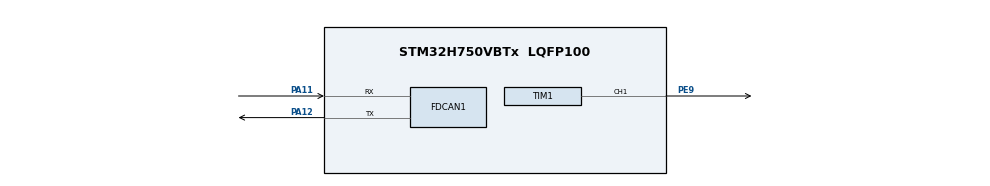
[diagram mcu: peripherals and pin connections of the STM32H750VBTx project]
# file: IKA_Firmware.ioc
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CORTEX_M7.default_mode_Activation=1
FDCAN1.CalculateBaudRateNominal=1000000
FDCAN1.CalculateTimeBitNominal=1000
FDCAN1.CalculateTimeQuantumNominal=12.5
FDCAN1.DataSyncJumpWidth=2
FDCAN1.DataTimeSeg1=7
FDCAN1.DataTimeSeg2=2
FDCAN1.FrameFormat=FDCAN_FRAME_FD_BRS
FDCAN1.NominalPrescaler=1
FDCAN1.NominalTimeSeg1=63
FDCAN1.NominalTimeSeg2=16
FDCAN1.RxFifo0ElmtSize=FDCAN_DATA_BYTES_64
FDCAN1.RxFifo0ElmtsNbr=32
FDCAN1.RxFifo1ElmtSize=FDCAN_DATA_BYTES_64
FDCAN1.RxFifo1ElmtsNbr=32
FDCAN1.StdFiltersNbr=16
FDCAN1.TxElmtSize=FDCAN_DATA_BYTES_64
FDCAN1.TxFifoQueueElmtsNbr=16
FREERTOS.RecursiveMutexes01=canTxMutex,Dynamic,NULL,Available;bmsMutex,Dynamic,NULL,Available;stateMutex,Dynamic,NULL,Available;targetSpeedMutex,Dynamic,NULL,Available
FREERTOS.Tasks01=defaultTask,24,128,StartDefaultTask,Default,NULL,Dynamic,NULL,NULL;ControlTask,48,512,StartControlTask,Default,NULL,Dynamic,NULL,NULL;SafetyTask,40,512,StartSafetyTask,Default,NULL,Dynamic,NULL,NULL;TelemetryTask,24,256,StartTelemetryTask,Default,NULL,Dynamic,NULL,NULL
FREERTOS.configENABLE_FPU=1
Mcu.Family=STM32H7
Mcu.Name=STM32H750VBTx
Mcu.Package=LQFP100
Mdma.MDMA_Channel0.Request0=SW
Mdma.MDMA_Channel0.RequestsNb=1
Mdma.MDMA_Channel0.SW.0.BlockCount=0
Mdma.MDMA_Channel0.SW.0.BlockDataLength=0
Mdma.MDMA_Channel0.SW.0.BufferTransferLength=1
Mdma.MDMA_Channel0.SW.0.CircularMode=MDMA_LINEAR_LIST
Mdma.MDMA_Channel0.SW.0.DataAlignment=MDMA_DATAALIGN_PACKENABLE
Mdma.MDMA_Channel0.SW.0.DestBlockAddressOffset=0
Mdma.MDMA_Channel0.SW.0.DestBurst=MDMA_DEST_BURST_SINGLE
Mdma.MDMA_Channel0.SW.0.DestDataSize=MDMA_DEST_DATASIZE_BYTE
Mdma.MDMA_Channel0.SW.0.DestinationInc=MDMA_DEST_INC_BYTE
Mdma.MDMA_Channel0.SW.0.DstAddress=0
Mdma.MDMA_Channel0.SW.0.Endianness=MDMA_LITTLE_ENDIANNESS_PRESERVE
Mdma.MDMA_Channel0.SW.0.Instance=MDMA_Channel0
Mdma.MDMA_Channel0.SW.0.MaskAddress=0
Mdma.MDMA_Channel0.SW.0.MaskData=0
Mdma.MDMA_Channel0.SW.0.Priority=MDMA_PRIORITY_LOW
Mdma.MDMA_Channel0.SW.0.Rank=First
Mdma.MDMA_Channel0.SW.0.SourceBlockAddressOffset=0
Mdma.MDMA_Channel0.SW.0.SourceBurst=MDMA_SOURCE_BURST_SINGLE
Mdma.MDMA_Channel0.SW.0.SourceDataSize=MDMA_SRC_DATASIZE_BYTE
Mdma.MDMA_Channel0.SW.0.SourceInc=MDMA_SRC_INC_BYTE
Mdma.MDMA_Channel0.SW.0.SrcAddress=0
Mdma.MDMA_Channel0.SW.0.TransferTriggerMode=MDMA_BUFFER_TRANSFER
Mdma.RequestSet0=MDMA_Channel0
Mdma.RequestSetsNb=1
NVIC.FDCAN1_IT0_IRQn=true\:5\:0\:false\:false\:true\:true\:true\:true\:true
NVIC.FDCAN1_IT1_IRQn=true\:5\:0\:true\:false\:true\:true\:true\:true\:true
NVIC.MDMA_IRQn=true\:6\:0\:true\:false\:true\:false\:false\:true\:true
NVIC.PriorityGroup=NVIC_PRIORITYGROUP_4
NVIC.TIM6_DAC_IRQn=true\:15\:0\:false\:false\:true\:false\:false\:true\:true
NVIC.TimeBase=TIM6_DAC_IRQn
NVIC.TimeBaseIP=TIM6
PA11.Mode=FDCAN_Activate
PA11.Signal=FDCAN1_RX
PA12.Mode=FDCAN_Activate
PA12.Signal=FDCAN1_TX
PE9.Signal=S_TIM1_CH1
ProjectManager.HeapSize=0x200
ProjectManager.StackSize=0x400
ProjectManager.TargetToolchain=STM32CubeIDE
RCC.ADCFreq_Value=160000000
RCC.APB1Freq_Value=64000000
RCC.APB2Freq_Value=64000000
RCC.APB3Freq_Value=64000000
RCC.APB4Freq_Value=64000000
RCC.CortexFreq_Value=64000000
RCC.DIVM1=8
RCC.DIVM2=8
RCC.DIVN2=40
RCC.DIVQ2=4
RCC.FDCANCLockSelection=RCC_FDCANCLKSOURCE_PLL2
RCC.HCLKFreq_Value=64000000
RCC.PLL2FRACN=0
RCC.PWR_Regulator_Voltage_Scale=PWR_REGULATOR_VOLTAGE_SCALE1
RCC.SYSCLKFreq_VALUE=64000000
RCC.USBFreq_Value=516000000
SH.S_TIM1_CH1.0=TIM1_CH1,PWM Generation1 CH1
TIM1.Channel-PWM\ Generation1\ CH1=TIM_CHANNEL_1
TIM1.Period=999
TIM1.Prescaler=3
VP_FREERTOS_VS_CMSIS_V2.Mode=CMSIS_V2
VP_IWDG1_VS_IWDG.Mode=IWDG_Activate
VP_MEMORYMAP_VS_MEMORYMAP.Mode=CurAppReg
VP_SYS_VS_tim6.Mode=TIM6
board=custom

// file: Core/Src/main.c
/* USER CODE BEGIN Header */
/**
  ******************************************************************************
  * @file           : main.c
  * @brief          : Main program body
  ******************************************************************************
  * @attention
  *
  * Copyright (c) 2026 STMicroelectronics.
  * All rights reserved.
  *
  * This software is licensed under terms that can be found in the LICENSE file
  * in the root directory of this software component.
  * If no LICENSE file comes with this software, it is provided AS-IS.
  *
  ******************************************************************************
  */
/* USER CODE END Header */
#include "main.h"
#include "FreeRTOS.h"
#include "cmsis_os2.h"
#include "fdcan.h"
#include "iwdg.h"
#include "mdma.h"
#include "tim.h"
#include "gpio.h"

/* USER CODE BEGIN Includes */
#include "can_comm.h"        /* can_init()            */
#include "can_dma_buffer.h"  /* can_dma_buffer_init() */
#include "blackbox.h"
/* USER CODE END Includes */

void SystemClock_Config(void);
static void MPU_Config(void);
void MX_FREERTOS_Init(void);

int main(void)
{

  /* MPU Configuration--------------------------------------------------------*/
  MPU_Config();

  /* MCU Configuration--------------------------------------------------------*/

  /* Reset of all peripherals, Initializes the Flash interface and the Systick. */
  HAL_Init();

  /* Configure the system clock */
  SystemClock_Config();

  /* Initialize all configured peripherals */
  MX_GPIO_Init();
  MX_MDMA_Init();
  MX_FDCAN1_Init();
  MX_IWDG1_Init();
  MX_TIM1_Init();
  /* USER CODE BEGIN 2 */
  /*
   * Sıralama kritik — scheduler başlamadan önce:
   *
   * 1) can_init()           : FDCAN filtrelerini + kesmelerini aktif eder.
   * FDCAN ISR (RxFifo0Callback) artık ateşlenebilir.
   *
   * 2) can_dma_buffer_init(): Ring buffer'ı sıfırlar.
   * Bu MUTLAKA can_init()'ten sonra ve
   * osKernelInitialize()'dan önce çağrılmalı.
   * Aksi hâlde ISR, henüz hazır olmayan buffer'a
   * frame yazmaya çalışabilir → tanımsız davranış.
   */
  can_init();
  can_dma_buffer_init();

  /* ============================================================
     FDCAN VE MDMA KESME (NVIC) ÖNCELİKLERİ
     FreeRTOS güvenli sınırı: 5 (Sayı küçüldükçe öncelik artar)
     ============================================================ */

  /* 1) FDCAN1 Kesmeleri: Öncelik 5 (En yüksek güvenli FreeRTOS önceliği) */
  HAL_NVIC_SetPriority(FDCAN1_IT0_IRQn, 5, 0);
  HAL_NVIC_SetPriority(FDCAN1_IT1_IRQn, 5, 0);
  HAL_NVIC_EnableIRQ(FDCAN1_IT0_IRQn);
  HAL_NVIC_EnableIRQ(FDCAN1_IT1_IRQn);

  /* 2) MDMA Kesmesi: Öncelik 6
     FDCAN'in frame yakalama işlemini bölmemesi için bir tık düşük öncelik. */
  HAL_NVIC_SetPriority(MDMA_IRQn, 6, 0);
  HAL_NVIC_EnableIRQ(MDMA_IRQn);
  /* USER CODE END 2 */

  /* Init scheduler */
  osKernelInitialize();  /* Call init function for freertos objects (in cmsis_os2.c) */
  MX_FREERTOS_Init();

  /* KRİTİK EKLENTİ: Backup SRAM'i ve Blackbox'ı başlat */
  blackbox_init();

  /* Start scheduler */
  osKernelStart();

  /* We should never get here as control is now taken by the scheduler */

  /* Infinite loop */
  while (1)
  {

  }
}

void SystemClock_Config(void)
{
  RCC_OscInitTypeDef RCC_OscInitStruct = {0};
  RCC_ClkInitTypeDef RCC_ClkInitStruct = {0};

  /** Supply configuration update enable
  */
  HAL_PWREx_ConfigSupply(PWR_LDO_SUPPLY);

  /** Configure the main internal regulator output voltage
  */
  __HAL_PWR_VOLTAGESCALING_CONFIG(PWR_REGULATOR_VOLTAGE_SCALE1);

  while(!__HAL_PWR_GET_FLAG(PWR_FLAG_VOSRDY)) {}

  /** Macro to configure the PLL clock source
  */
  __HAL_RCC_PLL_PLLSOURCE_CONFIG(RCC_PLLSOURCE_HSI);

  /** Initializes the RCC Oscillators according to the specified parameters
  * in the RCC_OscInitTypeDef structure.
  */
  RCC_OscInitStruct.OscillatorType = RCC_OSCILLATORTYPE_HSI|RCC_OSCILLATORTYPE_LSI;
  RCC_OscInitStruct.HSIState = RCC_HSI_DIV1;
  RCC_OscInitStruct.HSICalibrationValue = RCC_HSICALIBRATION_DEFAULT;
  RCC_OscInitStruct.LSIState = RCC_LSI_ON;
  RCC_OscInitStruct.PLL.PLLState = RCC_PLL_NONE;
  if (HAL_RCC_OscConfig(&RCC_OscInitStruct) != HAL_OK)
  {
    Error_Handler();
  }

  /** Initializes the CPU, AHB and APB buses clocks
  */
  RCC_ClkInitStruct.ClockType = RCC_CLOCKTYPE_HCLK|RCC_CLOCKTYPE_SYSCLK
                              |RCC_CLOCKTYPE_PCLK1|RCC_CLOCKTYPE_PCLK2
                              |RCC_CLOCKTYPE_D3PCLK1|RCC_CLOCKTYPE_D1PCLK1;
  RCC_ClkInitStruct.SYSCLKSource = RCC_SYSCLKSOURCE_HSI;
  RCC_ClkInitStruct.SYSCLKDivider = RCC_SYSCLK_DIV1;
  RCC_ClkInitStruct.AHBCLKDivider = RCC_HCLK_DIV1;
  RCC_ClkInitStruct.APB3CLKDivider = RCC_APB3_DIV1;
  RCC_ClkInitStruct.APB1CLKDivider = RCC_APB1_DIV1;
  RCC_ClkInitStruct.APB2CLKDivider = RCC_APB2_DIV1;
  RCC_ClkInitStruct.APB4CLKDivider = RCC_APB4_DIV1;

  if (HAL_RCC_ClockConfig(&RCC_ClkInitStruct, FLASH_LATENCY_0) != HAL_OK)
  {
    Error_Handler();
  }
}

 /* MPU Configuration */

/* MPU Configuration */
void MPU_Config(void)
{
    MPU_Region_InitTypeDef MPU_InitStruct = {0};

    /* Ayarlamalar yapılırken MPU'yu geçici olarak devre dışı bırak */
    HAL_MPU_Disable();

    /* DİKKAT: 4GB'lık arka plan tanımlamasını SİLDİK. İşlemcinin kendi donanımsal
       Flash ve SRAM haritasını kullanabilmesi için ayarı PRIVILEGED_DEFAULT'a bırakıyoruz. */

    /* ====================================================================
       BÖLGE 0: FDCAN Message RAM (MRAM)
       ==================================================================== */
    MPU_InitStruct.Enable           = MPU_REGION_ENABLE;
    MPU_InitStruct.Number           = MPU_REGION_NUMBER0; /* Numara 0'a çekildi */
    MPU_InitStruct.BaseAddress      = 0x40008000;
    MPU_InitStruct.Size             = MPU_REGION_SIZE_32KB;
    MPU_InitStruct.SubRegionDisable = 0x00;
    MPU_InitStruct.TypeExtField     = MPU_TEX_LEVEL0; /* Device Memory */
    MPU_InitStruct.AccessPermission = MPU_REGION_FULL_ACCESS;
    MPU_InitStruct.DisableExec      = MPU_INSTRUCTION_ACCESS_DISABLE;
    MPU_InitStruct.IsShareable      = MPU_ACCESS_SHAREABLE;
    MPU_InitStruct.IsCacheable      = MPU_ACCESS_NOT_CACHEABLE;
    MPU_InitStruct.IsBufferable     = MPU_ACCESS_NOT_BUFFERABLE;
    HAL_MPU_ConfigRegion(&MPU_InitStruct);

    /* ====================================================================
       BÖLGE 1: Siyah Kutu (Blackbox) Backup SRAM
       ==================================================================== */
    MPU_InitStruct.Enable           = MPU_REGION_ENABLE;
    MPU_InitStruct.Number           = MPU_REGION_NUMBER1; /* Numara 1'e çekildi */
    MPU_InitStruct.BaseAddress      = 0x38800000;
    MPU_InitStruct.Size             = MPU_REGION_SIZE_4KB;
    MPU_InitStruct.SubRegionDisable = 0x00;
    MPU_InitStruct.TypeExtField     = MPU_TEX_LEVEL1; /* Normal Memory */
    MPU_InitStruct.AccessPermission = MPU_REGION_FULL_ACCESS;
    MPU_InitStruct.DisableExec      = MPU_INSTRUCTION_ACCESS_DISABLE;
    MPU_InitStruct.IsShareable      = MPU_ACCESS_SHAREABLE;
    MPU_InitStruct.IsCacheable      = MPU_ACCESS_NOT_CACHEABLE;
    MPU_InitStruct.IsBufferable     = MPU_ACCESS_NOT_BUFFERABLE;
    HAL_MPU_ConfigRegion(&MPU_InitStruct);

    /* MPU'yu aktif et ve tanımlanmayan alanları donanım standartlarına bırak */
    HAL_MPU_Enable(MPU_PRIVILEGED_DEFAULT);
}

void HAL_TIM_PeriodElapsedCallback(TIM_HandleTypeDef *htim)
{
  if (htim->Instance == TIM6)
  {
    HAL_IncTick();
  }
}

void Error_Handler(void)
{
  __disable_irq();
  while (1)
  {
  }
}

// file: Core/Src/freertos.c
/* USER CODE BEGIN Header */
/**
  ******************************************************************************
  * File Name          : freertos.c
  * Description        : Code for freertos applications
  ******************************************************************************
  */
/* USER CODE END Header */

#include "FreeRTOS.h"
#include "task.h"
#include "main.h"
#include "FreeRTOS.h"
#include "cmsis_os2.h"

/* USER CODE BEGIN Includes */
#include "system_config.h"
#include "bms_emus_can.h"
#include "can_comm.h"
#include "can_dma_buffer.h"
#include "heartbeat.h"
#include "vel_profile.h"
#include "state_machine.h"
#include "motor_control.h"
#include "brake_control.h"
#include "current_limiter.h"
#include "safety.h"
#include "failsafe.h"
#include "protocol.h"
#include "error_codes.h"
#include "pid.h"
#include "odrive_sm.h"
#include "iwdg.h"
#include "imu_filter.h"
#include "pid_tuner.h"
#include "weapon_control.h"
#include "drive_mode.h"
#include "safe_mode.h"
#include "blackbox.h"
/* USER CODE END Includes */

/* USER CODE BEGIN PD */
#define CONTROL_PERIOD_MS       10U
#define SAFETY_PERIOD_MS        50U
#define TELEMETRY_PERIOD_MS     100U
/* USER CODE END PD */

/* USER CODE BEGIN Variables */

/* Hata takibi için can_comm.c'den alınan global değişkenler */
extern uint32_t can_rx_error_count;
extern uint32_t can_protocol_error_count;
extern FDCAN_HandleTypeDef hfdcan1;

/* BMS verisi — bmsMutex */
BMS_Data_t      g_bmsData;
/* Araç durum makinesi — stateMutex */
vehicle_state_t g_vehicleState;
/* ROS heartbeat izleyici — stateMutex */
heartbeat_t     g_heartbeat;
/* ROS'tan gelen hedef hız (mm/s) ve sürüş parametreleri — targetSpeedMutex */
float           g_targetSpeed_mm_s;
uint8_t         g_surusModu;
uint8_t         g_kontrol;
/* Hata maskesi — stateMutex */
uint8_t         g_errorMask;
uint8_t         g_errorDetail; //Detay hataları için bit çakışması olmaması içindir.

/* SADECE ControlTask'a ait — mutex gerekmez */
static vel_profile_t     s_velProfile;
static PID_Controller_t  s_pid;
static current_limiter_t s_currentLimiter;
static odrive_sm_t       s_odriveSm;
volatile float g_imu_angle_deg = 0.0f;
static imu_filter_t      s_imuFilter;

/* --- SİMÜLASYON VE TUNING EKLENTİLERİ --- */
#ifdef DEBUG_SIMULATION
static imu_sim_state_t   s_imuSim;
static pid_tuner_t       s_pidTuner;
static uint8_t           s_pid_step_started = 0u;
#endif

/* CubeMX'in SİLEMEYECEĞİ IMU Mutex Tanımlaması */
osMutexId_t imuMutexHandle;
const osMutexAttr_t imuMutex_attributes = {
  .name = "imuMutex",
  .attr_bits = osMutexRecursive,
};
/* ----------------------- */

/* USER CODE END Variables */
/* Definitions for defaultTask */
osThreadId_t defaultTaskHandle;
const osThreadAttr_t defaultTask_attributes = {
  .name = "defaultTask",
  .stack_size = 128 * 4,
  .priority = (osPriority_t) osPriorityNormal,
};
/* Definitions for ControlTask */
osThreadId_t ControlTaskHandle;
const osThreadAttr_t ControlTask_attributes = {
  .name = "ControlTask",
  .stack_size = 512 * 4,
  .priority = (osPriority_t) osPriorityRealtime,
};
/* Definitions for SafetyTask */
osThreadId_t SafetyTaskHandle;
const osThreadAttr_t SafetyTask_attributes = {
  .name = "SafetyTask",
  .stack_size = 512 * 4,
  .priority = (osPriority_t) osPriorityHigh,
};
/* Definitions for TelemetryTask */
osThreadId_t TelemetryTaskHandle;
const osThreadAttr_t TelemetryTask_attributes = {
  .name = "TelemetryTask",
  .stack_size = 256 * 4,
  .priority = (osPriority_t) osPriorityNormal,
};
/* Definitions for canTxMutex */
osMutexId_t canTxMutexHandle;
const osMutexAttr_t canTxMutex_attributes = {
  .name = "canTxMutex",
  .attr_bits = osMutexRecursive,
};
/* Definitions for bmsMutex */
osMutexId_t bmsMutexHandle;
const osMutexAttr_t bmsMutex_attributes = {
  .name = "bmsMutex",
  .attr_bits = osMutexRecursive,
};
/* Definitions for stateMutex */
osMutexId_t stateMutexHandle;
const osMutexAttr_t stateMutex_attributes = {
  .name = "stateMutex",
  .attr_bits = osMutexRecursive,
};
/* Definitions for targetSpeedMutex */
osMutexId_t targetSpeedMutexHandle;
const osMutexAttr_t targetSpeedMutex_attributes = {
  .name = "targetSpeedMutex",
  .attr_bits = osMutexRecursive,
};

void StartDefaultTask(void *argument);
void StartControlTask(void *argument);
void StartSafetyTask(void *argument);
void StartTelemetryTask(void *argument);

void MX_FREERTOS_Init(void); /* (MISRA C 2004 rule 8.1) */

void MX_FREERTOS_Init(void) {
  /* USER CODE BEGIN Init */
  BMS_Init(&g_bmsData);
  heartbeat_init(&g_heartbeat);
  g_targetSpeed_mm_s = 0.0f;
  g_surusModu        = 0u;
  g_kontrol          = 0u;
  g_errorMask        = 0u;
  /* USER CODE END Init */

  /* Create the recursive mutex(es) */
  /* creation of canTxMutex */
  canTxMutexHandle = osMutexNew(&canTxMutex_attributes);

  /* creation of bmsMutex */
  bmsMutexHandle = osMutexNew(&bmsMutex_attributes);

  /* creation of stateMutex */
  stateMutexHandle = osMutexNew(&stateMutex_attributes);

  /* creation of targetSpeedMutex */
  targetSpeedMutexHandle = osMutexNew(&targetSpeedMutex_attributes);

  /* USER CODE BEGIN RTOS_MUTEX */
  imuMutexHandle = osMutexNew(&imuMutex_attributes);
  /* USER CODE END RTOS_MUTEX */

  /* Create the thread(s) */
  /* creation of defaultTask */
  defaultTaskHandle = osThreadNew(StartDefaultTask, NULL, &defaultTask_attributes);

  /* creation of ControlTask */
  ControlTaskHandle = osThreadNew(StartControlTask, NULL, &ControlTask_attributes);

  /* creation of SafetyTask */
  SafetyTaskHandle = osThreadNew(StartSafetyTask, NULL, &SafetyTask_attributes);

  /* creation of TelemetryTask */
  TelemetryTaskHandle = osThreadNew(StartTelemetryTask, NULL, &TelemetryTask_attributes);

}

void StartDefaultTask(void *argument)
{
  /* USER CODE BEGIN StartDefaultTask */
  for (;;) { osDelay(1000); }
  /* USER CODE END StartDefaultTask */
}

/* USER CODE BEGIN Header_StartControlTask */
/**
  * @brief ControlTask — 100 Hz ana kontrol dongusu.
  */
/* USER CODE END Header_StartControlTask */
void StartControlTask(void *argument)
{
  /* USER CODE BEGIN StartControlTask */
  motor_init();
  brake_init();
  //TIM3 kullandığımızı varsaydığım için eskiden encoder_start ile TIM3 donanımı başlatılıyordu.
  failsafe_init();
  state_machine_init();
  weapon_init(); /* Taret silah sistemi ve röleleri başlat */

  vel_profile_init(&s_velProfile,
                   VEL_PROFILE_MAX_ACCEL_MM_S2,
                   VEL_PROFILE_MAX_DECEL_MM_S2,
                   VEL_PROFILE_MAX_JERK_MM_S3,
                   VEL_PROFILE_SCURVE);

  PID_Init(&s_pid, PID_KP, PID_KI, PID_KD, PID_OUT_MIN, PID_OUT_MAX);
  PID_SetHoldOffset(PID_HOLD_OFFSET);

  current_limiter_init(&s_currentLimiter,
                       CURRENT_LIM_NOMINAL_A,
                       CURRENT_LIM_PEAK_A,
                       CURRENT_LIM_MIN_A);

  odrive_sm_init(&s_odriveSm);

  imu_filter_init(&s_imuFilter, IMU_FILTER_ALPHA);

#ifdef DEBUG_SIMULATION
  imu_sim_init(&s_imuSim, IMU_SIM_NOISE_SCALE, 1u);
  pid_tuner_init(&s_pidTuner, PID_KP, PID_KI, PID_KD);
  pid_tuner_apply(&s_pidTuner, &s_pid);
  s_pid_step_started = 0u;
#endif

  const float DT_S = (float)CONTROL_PERIOD_MS / 1000.0f;
  TickType_t xLastWake = xTaskGetTickCount();

  for (;;)
  {
    /* 1) CAN RX ring buffer'i bosalt */
    {
      can_dma_frame_t frame;
      while (can_dma_buffer_pop(&frame))
      {
        if (frame.identifier >= BMS_BASE_ID &&
            frame.identifier <= (BMS_BASE_ID + BMS_OFFSET_TEMP_END))
        {
          osMutexAcquire(bmsMutexHandle, osWaitForever);
          BMS_ParseCanMessage(frame.identifier, frame.data, frame.data_length, &g_bmsData);
          osMutexRelease(bmsMutexHandle);
        }
        else if (frame.identifier == HEARTBEAT_CAN_ID)
        {
          osMutexAcquire(stateMutexHandle, osWaitForever);
          heartbeat_kick(&g_heartbeat, frame.data);
          osMutexRelease(stateMutexHandle);
        }
        else if (frame.identifier == 0x100U)
        {
          command_t cmd;
          if (proto_unpack_command(frame.data, &cmd) != 0)
          {
            osMutexAcquire(targetSpeedMutexHandle, osWaitForever);
            g_targetSpeed_mm_s = cmd.hizlan * 1000.0f;
            g_surusModu        = cmd.surus_modu;
            g_kontrol          = cmd.kontrol;
            osMutexRelease(targetSpeedMutexHandle);
            failsafe_kick();
          }
          else
          {
            can_protocol_error_count++;
          }
        }
        else if (ODRIVE_IS_MY_MSG(frame.identifier))
        {
          /* 1. Gelen mesajı (Encoder, IQ, Heartbeat, vb.) önbelleğe al */
          odrive_process_rx(frame.identifier, frame.data, frame.data_length);
        }
      }

      if (HAL_FDCAN_GetRxFifoFillLevel(&hfdcan1, FDCAN_RX_FIFO0) >= 32)
      {
          can_rx_error_count++;
      }

      if (can_dma_buffer_get_overrun_count() > 0U)
      {
          can_rx_error_count += can_dma_buffer_get_overrun_count();
          can_dma_buffer_reset_stats();
      }
    }

    /* 2) Arac durumunu oku */
    vehicle_state_t state = state_machine_get();

    /* --- ODrive durum makinesi her döngüde (10 ms) güncellenir --- */
    odrive_sm_update(&s_odriveSm, state);

    /* 3) Failsafe ve Heartbeat timeout kontrolü (Şartlardan bağımsız her döngüde çalışır) */
    if(osMutexAcquire(stateMutexHandle , pdMS_TO_TICKS(2)) == osOK)
    {
    	heartbeat_check(&g_heartbeat);
    	osMutexRelease(stateMutexHandle);

    }
    failsafe_check();

    if (state == STATE_DRIVING && !failsafe_is_active())
    {
      float target_mm_s;
      uint8_t current_surus_modu;
      uint8_t current_kontrol;

      osMutexAcquire(targetSpeedMutexHandle, osWaitForever);
      target_mm_s        = g_targetSpeed_mm_s;
      current_surus_modu = g_surusModu;
      current_kontrol    = g_kontrol;
      osMutexRelease(targetSpeedMutexHandle);

      /* --- MOD, LİMP VE SİLAH KONTROLLERİ (GÜNCELLENDİ) --- */
      osMutexAcquire(stateMutexHandle, osWaitForever);
      uint8_t anlik_hata   = g_errorMask;
      uint8_t anlik_detay  = g_errorDetail;   // YENİ: detay hataları da oku
      osMutexRelease(stateMutexHandle);

      // safe_mode_check artık 3 parametre alıyor
      uint8_t safe_status = safe_mode_check(anlik_hata, anlik_detay, &s_velProfile, &s_currentLimiter);

      /* Kritik değilse sürüş modunu uygula (Limp mode'u ezmemesi için) */
      if (safe_status == 2) {
          drive_mode_update(current_surus_modu, &s_velProfile, &s_currentLimiter);
      }

      weapon_task_check();
      weapon_laser_set((current_kontrol & 0x01) ? 1 : 0);
      /* -------------------------------------- */

      float smoothed_mm_s = vel_profile_step(&s_velProfile, target_mm_s, DT_S);

      /* TIM3 Harici Enkoder yerine ODrive'ın kendi CAN FD hız verisini kullanıyoruz */
      const odrive_state_t *odrv_feedback = odrive_get_state();
      float measured_mm_s = odrive_turns_per_s_to_mps(odrv_feedback->encoder.vel_estimate) * 1000.0f;

      float busVoltage;
      osMutexAcquire(bmsMutexHandle, osWaitForever);
      busVoltage        = BMS_GetAvgCellVoltage(&g_bmsData) * (float)g_bmsData.cells_received;
      float motorTemp   = BMS_GetMaxCellTemp(&g_bmsData);
      float measuredCur = g_bmsData.current_A;
      osMutexRelease(bmsMutexHandle);

      current_limiter_update(&s_currentLimiter, busVoltage, motorTemp,
                             measuredCur, (float)CONTROL_PERIOD_MS);

      float ff_rad = g_imu_angle_deg * 0.01745329f;
      float ff_sin = ff_rad - (ff_rad * ff_rad * ff_rad) / 6.0f;
      if (ff_sin >  1.0f) ff_sin =  1.0f;
      if (ff_sin < -1.0f) ff_sin = -1.0f;
      float gravity_ff = GRAVITY_FEEDFORWARD * ff_sin;
      float pid_raw = PID_Compute_WithFeedForward(&s_pid, smoothed_mm_s,
                                                          measured_mm_s, DT_S,
                                                          gravity_ff);

      float pid_out = current_limiter_apply(&s_currentLimiter, pid_raw);

#ifdef DEBUG_SIMULATION
      {
          if (!s_pid_step_started)
          {
              pid_tuner_start_step(&s_pidTuner, 500.0f, HAL_GetTick());
              s_pid_step_started = 1u;
          }
          pid_tuner_step(&s_pidTuner, measured_mm_s, HAL_GetTick());
      }
#endif /* DEBUG_SIMULATION */

      {
          float gyro_dps        = 0.0f;
          float accel_angle_deg = 0.0f;

#ifdef DEBUG_SIMULATION
          imu_sim_step(&s_imuSim, DT_S, &gyro_dps, &accel_angle_deg);
#endif
          float angle = imu_filter_update(&s_imuFilter, gyro_dps, accel_angle_deg, DT_S);

          /* IMU açısını Mutex ile koruyarak yaz */
          if (osMutexAcquire(imuMutexHandle, osWaitForever) == osOK) {
              g_imu_angle_deg = angle;
              osMutexRelease(imuMutexHandle);
          }
      }

      brake_release();
      motor_set_target_speed(smoothed_mm_s);
      motor_set_output(pid_out);
    }
    else
    {
      vel_profile_reset(&s_velProfile);
      PID_Reset(&s_pid);
      brake_apply();
      motor_apply_fail_safe(1u);

      if (failsafe_is_hard_locked())
        odrive_sm_force_idle(&s_odriveSm);

#ifdef DEBUG_SIMULATION
      s_pid_step_started = 0u;
#endif
      imu_filter_reset(&s_imuFilter, 0.0f);
    }

    HAL_IWDG_Refresh(&hiwdg1);
    vTaskDelayUntil(&xLastWake, pdMS_TO_TICKS(CONTROL_PERIOD_MS));
  }
  //Odrive her loop ta çağırılıyor artık heartbeat mesajlarına bağımlı olmadan sürekli ve hızlı güncelliyor.
  /* USER CODE END StartControlTask */
}

void StartSafetyTask(void *argument)
{
  /* USER CODE BEGIN StartSafetyTask */
  Safety_Init();

  for (;;)
  {
    safety_status_t gpioStatus = Safety_Check();

    float minCellV, maxCellT;
    uint8_t bmsReceivedOk;
    osMutexAcquire(bmsMutexHandle, osWaitForever);
    minCellV      = BMS_GetMinCellVoltage(&g_bmsData);
    maxCellT      = BMS_GetMaxCellTemp(&g_bmsData);
    bmsReceivedOk = (g_bmsData.cells_received > 0u) ? 1u : 0u;
    osMutexRelease(bmsMutexHandle);

    uint8_t rosAlive = 0;
        /* Timeout ekleyerek SafetyTask'ın donmasını engelliyoruz */
        if (osMutexAcquire(stateMutexHandle, pdMS_TO_TICKS(5)) == osOK) {
            rosAlive = heartbeat_is_alive(&g_heartbeat);
            osMutexRelease(stateMutexHandle);
        }

    /* --- DEĞİŞEN KISIM: Ana hatalar ve detay hatalar ayrıldı --- */
    // ... (önceki kodlar)
    uint8_t mainErrors = 0u;
    uint8_t detailErrors = 0u;   // zaten var

    if (gpioStatus == SAFETY_ESTOP_ACTIVE)            ERR_SET(mainErrors, ERR_ESTOP_ACTIVE);
    if (gpioStatus == SAFETY_BMS_FAULT)               ERR_SET(mainErrors, ERR_BMS_FAULT);

    if (!rosAlive)                                    ERR_SET(detailErrors, ERR_DETAIL_HEARTBEAT_LOST);
    if (bmsReceivedOk && minCellV < BMS_MIN_CELL_VOLTAGE_V) ERR_SET(detailErrors, ERR_DETAIL_LOW_VOLTAGE);
    if (bmsReceivedOk && maxCellT > BMS_MAX_CELL_TEMP_C)    ERR_SET(detailErrors, ERR_DETAIL_HIGH_TEMP);

    osMutexAcquire(stateMutexHandle, osWaitForever);
    g_errorMask = mainErrors;
    g_errorDetail = detailErrors;   // YENİ satır

    // Durum makinesi geçişleri için ana hataları kullan (kritik hala aynı)
    if (ERR_IS_SET(mainErrors, ERR_ESTOP_ACTIVE) || ERR_IS_SET(mainErrors, ERR_BMS_FAULT))
    {
        state_machine_set(STATE_EMERGENCY);
        ERR_SET(g_errorMask, ERR_HARD_LATCH);
    }
    else if ( (detailErrors & (ERR_DETAIL_LOW_VOLTAGE | ERR_DETAIL_HIGH_TEMP | ERR_DETAIL_HEARTBEAT_LOST)) != 0u )
    {
        // Detay hatalardan biri varsa STANDBY'e geç, ama hard latch değil
        state_machine_set(STATE_STANDBY);
        ERR_SET(g_errorMask, ERR_FAILSAFE_ACTIVE);
    }
    else if (state_machine_get() != STATE_EMERGENCY)
    {
        state_machine_set(STATE_DRIVING);
    }

    osMutexRelease(stateMutexHandle);

    osDelay(pdMS_TO_TICKS(SAFETY_PERIOD_MS));
  }
  /* USER CODE END StartSafetyTask */
}

void StartTelemetryTask(void *argument)
{
  /* USER CODE BEGIN StartTelemetryTask */

  // DÜZELTME: blackbox_init() kaldırılırken silinen kritik adaptif telemetri değişkeni geri eklendi
  static uint8_t last_error_mask = 0u;

  for (;;)
  {
    /* 1) BMS Raporu */
    {
      bms_report_t bmsRpt = {0};
      osMutexAcquire(bmsMutexHandle, osWaitForever);
      bmsRpt.avg_voltage = BMS_GetAvgCellVoltage(&g_bmsData);
      bmsRpt.min_voltage = BMS_GetMinCellVoltage(&g_bmsData);
      bmsRpt.max_voltage = BMS_GetMaxCellVoltage(&g_bmsData);
      bmsRpt.current_a   = g_bmsData.current_A;
      bmsRpt.max_temp    = (int8_t)BMS_GetMaxCellTemp(&g_bmsData);
      bmsRpt.min_temp    = (int8_t)BMS_GetMinCellTemp(&g_bmsData);
      bmsRpt.cells       = g_bmsData.cells_received;
      bmsRpt.fault       = (BMS_GetMinCellVoltage(&g_bmsData) < BMS_MIN_CELL_VOLTAGE_V ||
                             BMS_GetMaxCellTemp(&g_bmsData)   > BMS_MAX_CELL_TEMP_C) ? 1u : 0u;
      osMutexRelease(bmsMutexHandle);

      if (osMutexAcquire(canTxMutexHandle, pdMS_TO_TICKS(5)) == osOK)
      {
        can_send_bms_report(&bmsRpt);
        osMutexRelease(canTxMutexHandle);
      }
    }

    /* 2) Hareket Telemetrisi */
        uint8_t current_errors = 0;
        vehicle_state_t current_state = state_machine_get();

        {
          report_t rpt = {0};

          /* --- DÜZELTME: Hedef hız yerine ÖLÇÜLEN hızı (enkoder) al --- */
          const odrive_state_t *odrv = odrive_get_state();
          if (odrv != NULL) {
              // ODrive enkoder hızını mm/s birimine çevirip yazıyoruz
              rpt.mevcut_hiz = odrive_turns_per_s_to_mps(odrv->encoder.vel_estimate) * 1000.0f;
          } else {
              rpt.mevcut_hiz = 0.0f;
          }
          /* ------------------------------------------------------------- */

          /* IMU açısını Mutex ile koruyarak oku */
          if (osMutexAcquire(imuMutexHandle, pdMS_TO_TICKS(5)) == osOK) {
              rpt.mevcut_egim = g_imu_angle_deg;
              osMutexRelease(imuMutexHandle);
          } else {
              rpt.mevcut_egim = 0.0f;
          }

          osMutexAcquire(stateMutexHandle, osWaitForever);
          current_errors = g_errorMask;
          rpt.hata    = (int8_t)g_errorMask;
          rpt.kontrol = (int8_t)current_state;
          osMutexRelease(stateMutexHandle);

          if (osMutexAcquire(canTxMutexHandle, pdMS_TO_TICKS(5)) == osOK)
          {
            can_send_report(&rpt);
            osMutexRelease(canTxMutexHandle);
          }
        }

    /* --- SİYAH KUTU SÜREKLİ LOGLAMA (10 Hz) --- */
    {
        blackbox_record_t r = {0};
        r.crash_timestamp_ms  = HAL_GetTick();
        r.vehicle_state       = current_state;
        r.error_mask          = current_errors;

        osMutexAcquire(targetSpeedMutexHandle, pdMS_TO_TICKS(5));
        r.target_speed_mm_s   = g_targetSpeed_mm_s;
        osMutexRelease(targetSpeedMutexHandle);

        const odrive_state_t *odrv = odrive_get_state();
        if (odrv != NULL) {
            r.measured_speed_mm_s = odrv->encoder.vel_estimate * 1000.0f;
            r.odrive_axis_error   = odrv->heartbeat.axis_error;
            r.odrive_axis_state   = odrv->heartbeat.axis_state;
        }

        osMutexAcquire(imuMutexHandle, pdMS_TO_TICKS(5));
        r.imu_angle_deg       = g_imu_angle_deg;
        osMutexRelease(imuMutexHandle);

        osMutexAcquire(bmsMutexHandle, pdMS_TO_TICKS(5));
        r.bus_voltage_v       = BMS_GetAvgCellVoltage(&g_bmsData) * (float)g_bmsData.cells_received;
        r.current_a           = g_bmsData.current_A;
        r.max_cell_temp_c     = (int8_t)BMS_GetMaxCellTemp(&g_bmsData);
        osMutexRelease(bmsMutexHandle);

        blackbox_log_step(&r);
    }

    /* --- ADAPTİF TELEMETRİ (DİNAMİK GECİKME) --- */
    uint32_t delay_ms = TELEMETRY_PERIOD_MS; /* Standart 100ms (10 Hz) */

    if (current_state == STATE_STANDBY && current_errors == 0u)
    {
        delay_ms = 500u;
    }

    if (current_errors != last_error_mask)
    {
        delay_ms = 10u;
    }

    last_error_mask = current_errors;

    osDelay(pdMS_TO_TICKS(delay_ms));
  }
  /* USER CODE END StartTelemetryTask */
}
